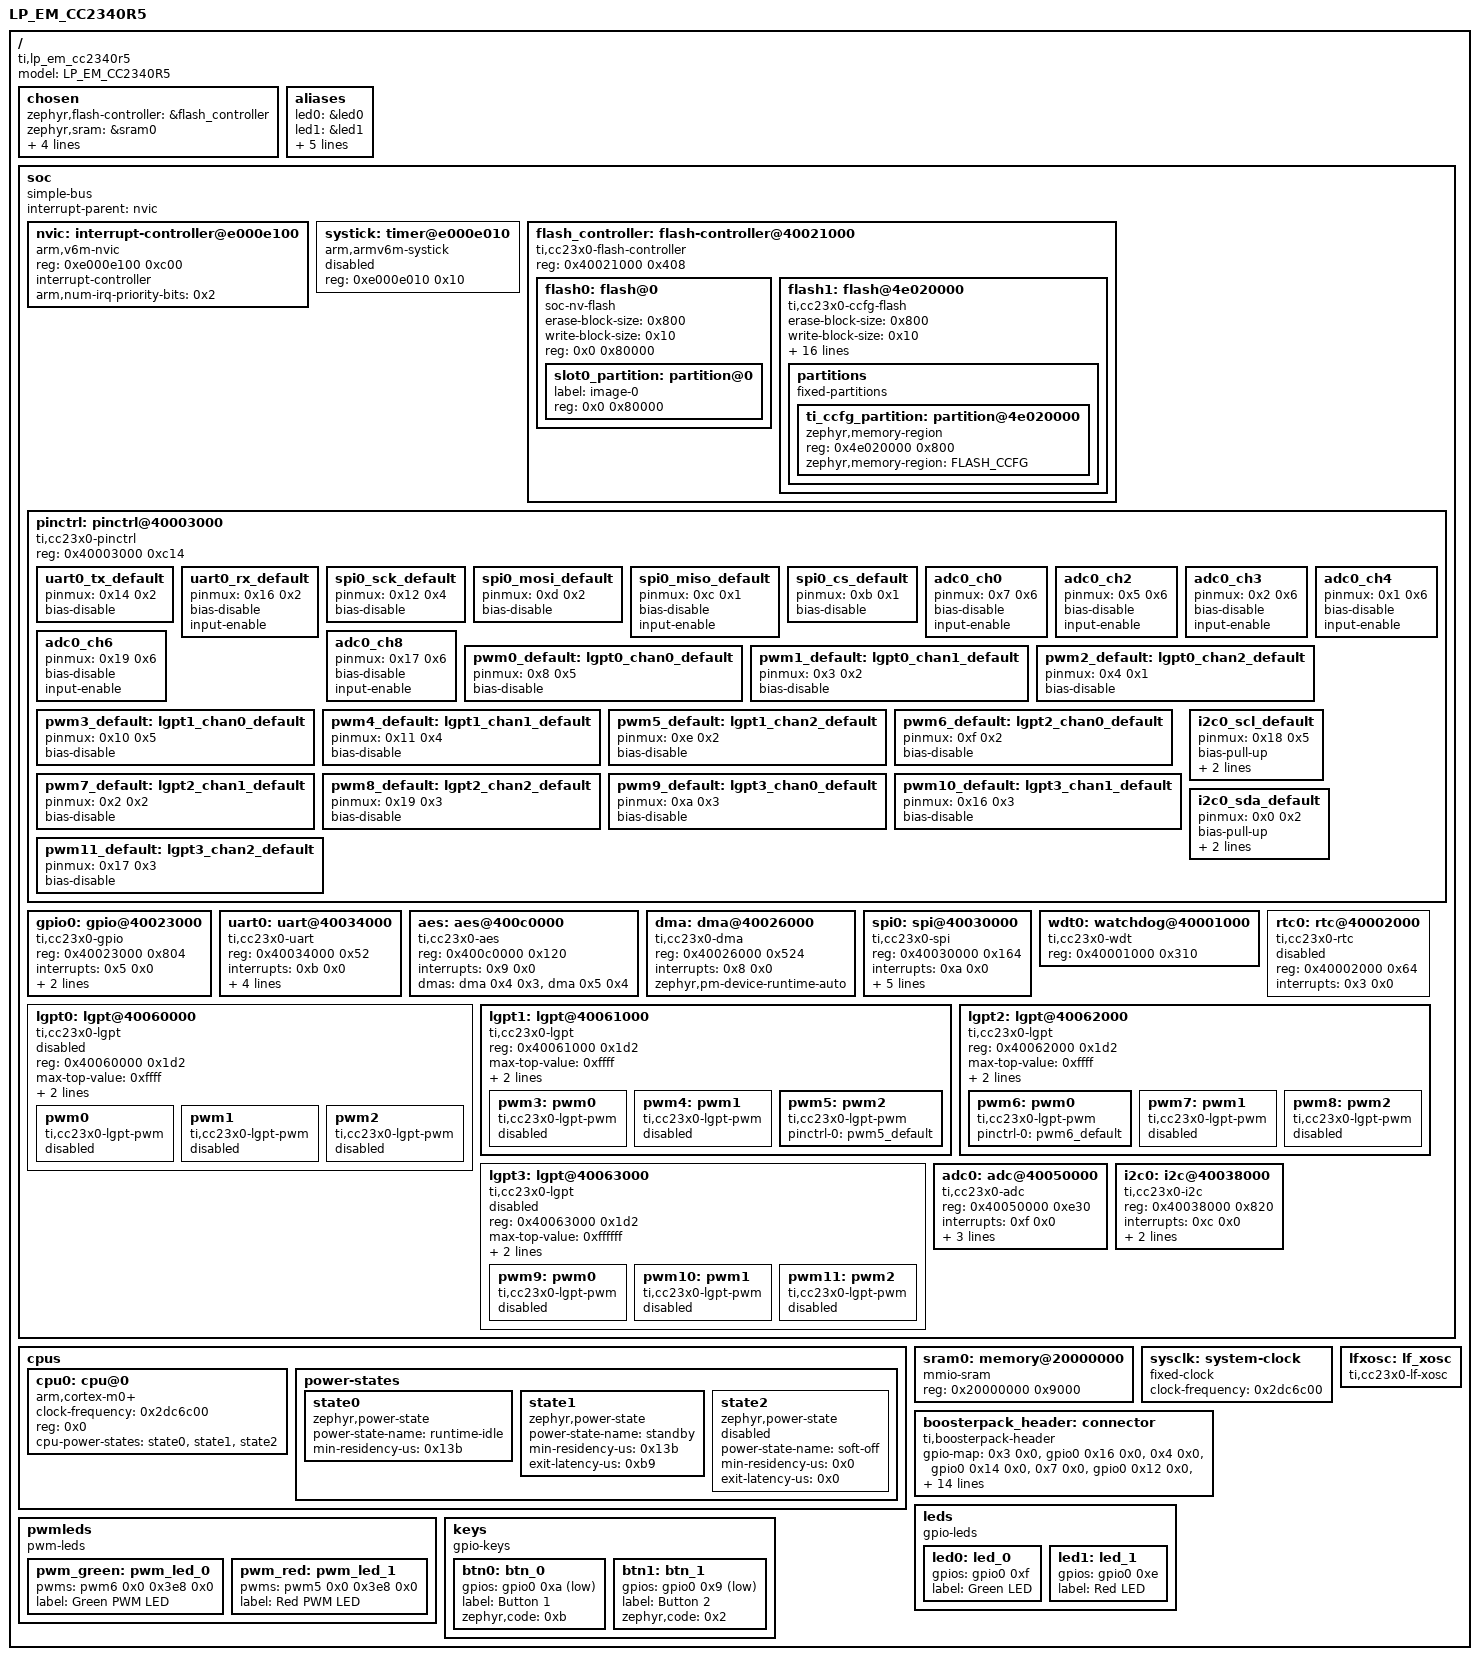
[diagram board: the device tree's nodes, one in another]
/dts-v1/;

/* node '/' defined in zephyr/dts/common/skeleton.dtsi:9 */
/ {
	#address-cells = < 0x1 >;         /* in zephyr/dts/common/skeleton.dtsi:10 */
	#size-cells = < 0x1 >;            /* in zephyr/dts/common/skeleton.dtsi:11 */
	model = "LP_EM_CC2340R5";         /* in zephyr/boards/ti/lp_em_cc2340r5/lp_em_cc2340r5.dts:18 */
	compatible = "ti,lp_em_cc2340r5"; /* in zephyr/boards/ti/lp_em_cc2340r5/lp_em_cc2340r5.dts:19 */

	/* node '/chosen' defined in zephyr/dts/common/skeleton.dtsi:13 */
	chosen {
		zephyr,flash-controller = &flash_controller; /* in zephyr/dts/arm/ti/cc23x0.dtsi:13 */
		zephyr,sram = &sram0;                        /* in zephyr/boards/ti/lp_em_cc2340r5/lp_em_cc2340r5.dts:22 */
		zephyr,flash = &flash0;                      /* in zephyr/boards/ti/lp_em_cc2340r5/lp_em_cc2340r5.dts:23 */
		zephyr,code-partition = &slot0_partition;    /* in zephyr/boards/ti/lp_em_cc2340r5/lp_em_cc2340r5.dts:24 */
		zephyr,console = &uart0;                     /* in zephyr/boards/ti/lp_em_cc2340r5/lp_em_cc2340r5.dts:25 */
		zephyr,shell-uart = &uart0;                  /* in zephyr/boards/ti/lp_em_cc2340r5/lp_em_cc2340r5.dts:26 */
	};

	/* node '/aliases' defined in zephyr/dts/common/skeleton.dtsi:15 */
	aliases {
		led0 = &led0;          /* in zephyr/boards/ti/lp_em_cc2340r5/lp_em_cc2340r5.dts:30 */
		led1 = &led1;          /* in zephyr/boards/ti/lp_em_cc2340r5/lp_em_cc2340r5.dts:31 */
		sw0 = &btn0;           /* in zephyr/boards/ti/lp_em_cc2340r5/lp_em_cc2340r5.dts:32 */
		sw1 = &btn1;           /* in zephyr/boards/ti/lp_em_cc2340r5/lp_em_cc2340r5.dts:33 */
		watchdog0 = &wdt0;     /* in zephyr/boards/ti/lp_em_cc2340r5/lp_em_cc2340r5.dts:34 */
		pwm-led0 = &pwm_green; /* in zephyr/boards/ti/lp_em_cc2340r5/lp_em_cc2340r5.dts:35 */
		pwm-led1 = &pwm_red;   /* in zephyr/boards/ti/lp_em_cc2340r5/lp_em_cc2340r5.dts:36 */
	};

	/* node '/soc' defined in zephyr/dts/arm/armv6-m.dtsi:6 */
	soc {
		#address-cells = < 0x1 >;     /* in zephyr/dts/arm/armv6-m.dtsi:7 */
		#size-cells = < 0x1 >;        /* in zephyr/dts/arm/armv6-m.dtsi:8 */
		compatible = "simple-bus";    /* in zephyr/dts/arm/armv6-m.dtsi:9 */
		interrupt-parent = < &nvic >; /* in zephyr/dts/arm/armv6-m.dtsi:10 */
		ranges;                       /* in zephyr/dts/arm/armv6-m.dtsi:11 */

		/* node '/soc/interrupt-controller@e000e100' defined in zephyr/dts/arm/armv6-m.dtsi:13 */
		nvic: interrupt-controller@e000e100 {
			#address-cells = < 0x1 >;            /* in zephyr/dts/arm/armv6-m.dtsi:14 */
			compatible = "arm,v6m-nvic";         /* in zephyr/dts/arm/armv6-m.dtsi:15 */
			reg = < 0xe000e100 0xc00 >;          /* in zephyr/dts/arm/armv6-m.dtsi:16 */
			interrupt-controller;                /* in zephyr/dts/arm/armv6-m.dtsi:17 */
			#interrupt-cells = < 0x2 >;          /* in zephyr/dts/arm/armv6-m.dtsi:18 */
			arm,num-irq-priority-bits = < 0x2 >; /* in zephyr/dts/arm/ti/cc23x0.dtsi:283 */
			phandle = < 0x1 >;                   /* in zephyr/dts/arm/armv6-m.dtsi:10 */
		};

		/* node '/soc/timer@e000e010' defined in zephyr/dts/arm/armv6-m.dtsi:21 */
		systick: timer@e000e010 {
			compatible = "arm,armv6m-systick"; /* in zephyr/dts/arm/armv6-m.dtsi:22 */
			reg = < 0xe000e010 0x10 >;         /* in zephyr/dts/arm/armv6-m.dtsi:23 */
			status = "disabled";               /* in zephyr/dts/arm/ti/cc23x0.dtsi:287 */
		};

		/* node '/soc/flash-controller@40021000' defined in zephyr/dts/arm/ti/cc23x0.dtsi:64 */
		flash_controller: flash-controller@40021000 {
			compatible = "ti,cc23x0-flash-controller"; /* in zephyr/dts/arm/ti/cc23x0.dtsi:65 */
			reg = < 0x40021000 0x408 >;                /* in zephyr/dts/arm/ti/cc23x0.dtsi:66 */
			#address-cells = < 0x1 >;                  /* in zephyr/dts/arm/ti/cc23x0.dtsi:67 */
			#size-cells = < 0x1 >;                     /* in zephyr/dts/arm/ti/cc23x0.dtsi:68 */

			/* node '/soc/flash-controller@40021000/flash@0' defined in zephyr/dts/arm/ti/cc23x0.dtsi:71 */
			flash0: flash@0 {
				compatible = "soc-nv-flash";  /* in zephyr/dts/arm/ti/cc23x0.dtsi:72 */
				erase-block-size = < 0x800 >; /* in zephyr/dts/arm/ti/cc23x0.dtsi:73 */
				write-block-size = < 0x10 >;  /* in zephyr/dts/arm/ti/cc23x0.dtsi:74 */
				reg = < 0x0 0x80000 >;        /* in zephyr/dts/arm/ti/cc2340r5.dtsi:19 */
				#address-cells = < 0x1 >;     /* in zephyr/dts/arm/ti/cc2340r5.dtsi:20 */
				#size-cells = < 0x1 >;        /* in zephyr/dts/arm/ti/cc2340r5.dtsi:21 */

				/* node '/soc/flash-controller@40021000/flash@0/partition@0' defined in zephyr/dts/arm/ti/cc2340r5.dtsi:23 */
				slot0_partition: partition@0 {
					label = "image-0";     /* in zephyr/dts/arm/ti/cc2340r5.dtsi:24 */
					reg = < 0x0 0x80000 >; /* in zephyr/dts/arm/ti/cc2340r5.dtsi:25 */
				};
			};

			/* node '/soc/flash-controller@40021000/flash@4e020000' defined in zephyr/dts/arm/ti/cc23x0.dtsi:78 */
			flash1: flash@4e020000 {
				compatible = "ti,cc23x0-ccfg-flash",
				             "soc-nv-flash";               /* in zephyr/dts/arm/ti/cc23x0.dtsi:79 */
				erase-block-size = < 0x800 >;              /* in zephyr/dts/arm/ti/cc23x0.dtsi:80 */
				write-block-size = < 0x10 >;               /* in zephyr/dts/arm/ti/cc23x0.dtsi:81 */
				reg = < 0x4e020000 0x800 >;                /* in zephyr/dts/arm/ti/cc2340r5.dtsi:31 */
				ti,bldr-vtor-flash = < 0x0 >;              /* in zephyr/dts/arm/ti/cc2340r5.dtsi:32 */
				ti,serial-io-cfg-index = < 0x0 >;          /* in zephyr/dts/arm/ti/cc2340r5.dtsi:33 */
				ti,debug-port;                             /* in zephyr/dts/arm/ti/cc2340r5.dtsi:34 */
				ti,energy-trace;                           /* in zephyr/dts/arm/ti/cc2340r5.dtsi:35 */
				ti,flash-verify;                           /* in zephyr/dts/arm/ti/cc2340r5.dtsi:36 */
				ti,flash-program;                          /* in zephyr/dts/arm/ti/cc2340r5.dtsi:37 */
				ti,chip-erase;                             /* in zephyr/dts/arm/ti/cc2340r5.dtsi:38 */
				ti,ret-to-factory;                         /* in zephyr/dts/arm/ti/cc2340r5.dtsi:39 */
				ti,wr-er-prot-sect0-31 = < 0xffffffff >;   /* in zephyr/dts/arm/ti/cc2340r5.dtsi:40 */
				ti,wr-er-prot-sect32-255 = < 0xffffffff >; /* in zephyr/dts/arm/ti/cc2340r5.dtsi:41 */
				ti,wr-er-prot-ccfg-sect = < 0x0 >;         /* in zephyr/dts/arm/ti/cc2340r5.dtsi:42 */
				ti,wr-er-prot-fcfg-sect = < 0x0 >;         /* in zephyr/dts/arm/ti/cc2340r5.dtsi:43 */
				ti,wr-er-prot-engr-sect = < 0x0 >;         /* in zephyr/dts/arm/ti/cc2340r5.dtsi:44 */
				ti,chip-er-retain-sect0-31 = < 0x0 >;      /* in zephyr/dts/arm/ti/cc2340r5.dtsi:45 */
				ti,chip-er-retain-sect32-255 = < 0x0 >;    /* in zephyr/dts/arm/ti/cc2340r5.dtsi:46 */

				/* node '/soc/flash-controller@40021000/flash@4e020000/partitions' defined in zephyr/dts/arm/ti/cc2340r5.dtsi:48 */
				partitions {
					compatible = "fixed-partitions"; /* in zephyr/dts/arm/ti/cc2340r5.dtsi:49 */
					#address-cells = < 0x1 >;        /* in zephyr/dts/arm/ti/cc2340r5.dtsi:50 */
					#size-cells = < 0x1 >;           /* in zephyr/dts/arm/ti/cc2340r5.dtsi:51 */

					/* node '/soc/flash-controller@40021000/flash@4e020000/partitions/partition@4e020000' defined in zephyr/dts/arm/ti/cc2340r5.dtsi:53 */
					ti_ccfg_partition: partition@4e020000 {
						compatible = "zephyr,memory-region"; /* in zephyr/dts/arm/ti/cc2340r5.dtsi:54 */
						reg = < 0x4e020000 0x800 >;          /* in zephyr/dts/arm/ti/cc2340r5.dtsi:55 */
						zephyr,memory-region = "FLASH_CCFG"; /* in zephyr/dts/arm/ti/cc2340r5.dtsi:56 */
					};
				};
			};
		};

		/* node '/soc/pinctrl@40003000' defined in zephyr/dts/arm/ti/cc23x0.dtsi:85 */
		pinctrl: pinctrl@40003000 {
			compatible = "ti,cc23x0-pinctrl"; /* in zephyr/dts/arm/ti/cc23x0.dtsi:86 */
			reg = < 0x40003000 0xc14 >;       /* in zephyr/dts/arm/ti/cc23x0.dtsi:87 */

			/* node '/soc/pinctrl@40003000/uart0_tx_default' defined in zephyr/boards/ti/lp_em_cc2340r5/lp_em_cc2340r5-pinctrl.dtsi:12 */
			uart0_tx_default: uart0_tx_default {
				pinmux = < 0x14 0x2 >; /* in zephyr/boards/ti/lp_em_cc2340r5/lp_em_cc2340r5-pinctrl.dtsi:13 */
				bias-disable;          /* in zephyr/boards/ti/lp_em_cc2340r5/lp_em_cc2340r5-pinctrl.dtsi:14 */
				phandle = < 0x5 >;     /* in zephyr/boards/ti/lp_em_cc2340r5/lp_em_cc2340r5.dts:95 */
			};

			/* node '/soc/pinctrl@40003000/uart0_rx_default' defined in zephyr/boards/ti/lp_em_cc2340r5/lp_em_cc2340r5-pinctrl.dtsi:17 */
			uart0_rx_default: uart0_rx_default {
				pinmux = < 0x16 0x2 >; /* in zephyr/boards/ti/lp_em_cc2340r5/lp_em_cc2340r5-pinctrl.dtsi:18 */
				bias-disable;          /* in zephyr/boards/ti/lp_em_cc2340r5/lp_em_cc2340r5-pinctrl.dtsi:19 */
				input-enable;          /* in zephyr/boards/ti/lp_em_cc2340r5/lp_em_cc2340r5-pinctrl.dtsi:20 */
				phandle = < 0x4 >;     /* in zephyr/boards/ti/lp_em_cc2340r5/lp_em_cc2340r5.dts:95 */
			};

			/* node '/soc/pinctrl@40003000/spi0_sck_default' defined in zephyr/boards/ti/lp_em_cc2340r5/lp_em_cc2340r5-pinctrl.dtsi:24 */
			spi0_sck_default: spi0_sck_default {
				pinmux = < 0x12 0x4 >; /* in zephyr/boards/ti/lp_em_cc2340r5/lp_em_cc2340r5-pinctrl.dtsi:25 */
				bias-disable;          /* in zephyr/boards/ti/lp_em_cc2340r5/lp_em_cc2340r5-pinctrl.dtsi:26 */
				phandle = < 0x8 >;     /* in zephyr/boards/ti/lp_em_cc2340r5/lp_em_cc2340r5.dts:109 */
			};

			/* node '/soc/pinctrl@40003000/spi0_mosi_default' defined in zephyr/boards/ti/lp_em_cc2340r5/lp_em_cc2340r5-pinctrl.dtsi:29 */
			spi0_mosi_default: spi0_mosi_default {
				pinmux = < 0xd 0x2 >; /* in zephyr/boards/ti/lp_em_cc2340r5/lp_em_cc2340r5-pinctrl.dtsi:30 */
				bias-disable;         /* in zephyr/boards/ti/lp_em_cc2340r5/lp_em_cc2340r5-pinctrl.dtsi:31 */
				phandle = < 0x9 >;    /* in zephyr/boards/ti/lp_em_cc2340r5/lp_em_cc2340r5.dts:109 */
			};

			/* node '/soc/pinctrl@40003000/spi0_miso_default' defined in zephyr/boards/ti/lp_em_cc2340r5/lp_em_cc2340r5-pinctrl.dtsi:34 */
			spi0_miso_default: spi0_miso_default {
				pinmux = < 0xc 0x1 >; /* in zephyr/boards/ti/lp_em_cc2340r5/lp_em_cc2340r5-pinctrl.dtsi:35 */
				bias-disable;         /* in zephyr/boards/ti/lp_em_cc2340r5/lp_em_cc2340r5-pinctrl.dtsi:36 */
				input-enable;         /* in zephyr/boards/ti/lp_em_cc2340r5/lp_em_cc2340r5-pinctrl.dtsi:37 */
				phandle = < 0xa >;    /* in zephyr/boards/ti/lp_em_cc2340r5/lp_em_cc2340r5.dts:109 */
			};

			/* node '/soc/pinctrl@40003000/spi0_cs_default' defined in zephyr/boards/ti/lp_em_cc2340r5/lp_em_cc2340r5-pinctrl.dtsi:40 */
			spi0_cs_default: spi0_cs_default {
				pinmux = < 0xb 0x1 >; /* in zephyr/boards/ti/lp_em_cc2340r5/lp_em_cc2340r5-pinctrl.dtsi:41 */
				bias-disable;         /* in zephyr/boards/ti/lp_em_cc2340r5/lp_em_cc2340r5-pinctrl.dtsi:42 */
				phandle = < 0xb >;    /* in zephyr/boards/ti/lp_em_cc2340r5/lp_em_cc2340r5.dts:109 */
			};

			/* node '/soc/pinctrl@40003000/adc0_ch0' defined in zephyr/boards/ti/lp_em_cc2340r5/lp_em_cc2340r5-pinctrl.dtsi:46 */
			adc0_ch0: adc0_ch0 {
				pinmux = < 0x7 0x6 >; /* in zephyr/boards/ti/lp_em_cc2340r5/lp_em_cc2340r5-pinctrl.dtsi:47 */
				bias-disable;         /* in zephyr/boards/ti/lp_em_cc2340r5/lp_em_cc2340r5-pinctrl.dtsi:48 */
				input-enable;         /* in zephyr/boards/ti/lp_em_cc2340r5/lp_em_cc2340r5-pinctrl.dtsi:49 */
				phandle = < 0xe >;    /* in zephyr/boards/ti/lp_em_cc2340r5/lp_em_cc2340r5.dts:122 */
			};

			/* node '/soc/pinctrl@40003000/adc0_ch2' defined in zephyr/boards/ti/lp_em_cc2340r5/lp_em_cc2340r5-pinctrl.dtsi:52 */
			adc0_ch2: adc0_ch2 {
				pinmux = < 0x5 0x6 >; /* in zephyr/boards/ti/lp_em_cc2340r5/lp_em_cc2340r5-pinctrl.dtsi:53 */
				bias-disable;         /* in zephyr/boards/ti/lp_em_cc2340r5/lp_em_cc2340r5-pinctrl.dtsi:54 */
				input-enable;         /* in zephyr/boards/ti/lp_em_cc2340r5/lp_em_cc2340r5-pinctrl.dtsi:55 */
				phandle = < 0xf >;    /* in zephyr/boards/ti/lp_em_cc2340r5/lp_em_cc2340r5.dts:122 */
			};

			/* node '/soc/pinctrl@40003000/adc0_ch3' defined in zephyr/boards/ti/lp_em_cc2340r5/lp_em_cc2340r5-pinctrl.dtsi:58 */
			adc0_ch3: adc0_ch3 {
				pinmux = < 0x2 0x6 >; /* in zephyr/boards/ti/lp_em_cc2340r5/lp_em_cc2340r5-pinctrl.dtsi:59 */
				bias-disable;         /* in zephyr/boards/ti/lp_em_cc2340r5/lp_em_cc2340r5-pinctrl.dtsi:60 */
				input-enable;         /* in zephyr/boards/ti/lp_em_cc2340r5/lp_em_cc2340r5-pinctrl.dtsi:61 */
				phandle = < 0x10 >;   /* in zephyr/boards/ti/lp_em_cc2340r5/lp_em_cc2340r5.dts:122 */
			};

			/* node '/soc/pinctrl@40003000/adc0_ch4' defined in zephyr/boards/ti/lp_em_cc2340r5/lp_em_cc2340r5-pinctrl.dtsi:64 */
			adc0_ch4: adc0_ch4 {
				pinmux = < 0x1 0x6 >; /* in zephyr/boards/ti/lp_em_cc2340r5/lp_em_cc2340r5-pinctrl.dtsi:65 */
				bias-disable;         /* in zephyr/boards/ti/lp_em_cc2340r5/lp_em_cc2340r5-pinctrl.dtsi:66 */
				input-enable;         /* in zephyr/boards/ti/lp_em_cc2340r5/lp_em_cc2340r5-pinctrl.dtsi:67 */
				phandle = < 0x11 >;   /* in zephyr/boards/ti/lp_em_cc2340r5/lp_em_cc2340r5.dts:122 */
			};

			/* node '/soc/pinctrl@40003000/adc0_ch6' defined in zephyr/boards/ti/lp_em_cc2340r5/lp_em_cc2340r5-pinctrl.dtsi:70 */
			adc0_ch6: adc0_ch6 {
				pinmux = < 0x19 0x6 >; /* in zephyr/boards/ti/lp_em_cc2340r5/lp_em_cc2340r5-pinctrl.dtsi:71 */
				bias-disable;          /* in zephyr/boards/ti/lp_em_cc2340r5/lp_em_cc2340r5-pinctrl.dtsi:72 */
				input-enable;          /* in zephyr/boards/ti/lp_em_cc2340r5/lp_em_cc2340r5-pinctrl.dtsi:73 */
				phandle = < 0x12 >;    /* in zephyr/boards/ti/lp_em_cc2340r5/lp_em_cc2340r5.dts:122 */
			};

			/* node '/soc/pinctrl@40003000/adc0_ch8' defined in zephyr/boards/ti/lp_em_cc2340r5/lp_em_cc2340r5-pinctrl.dtsi:76 */
			adc0_ch8: adc0_ch8 {
				pinmux = < 0x17 0x6 >; /* in zephyr/boards/ti/lp_em_cc2340r5/lp_em_cc2340r5-pinctrl.dtsi:77 */
				bias-disable;          /* in zephyr/boards/ti/lp_em_cc2340r5/lp_em_cc2340r5-pinctrl.dtsi:78 */
				input-enable;          /* in zephyr/boards/ti/lp_em_cc2340r5/lp_em_cc2340r5-pinctrl.dtsi:79 */
				phandle = < 0x13 >;    /* in zephyr/boards/ti/lp_em_cc2340r5/lp_em_cc2340r5.dts:122 */
			};

			/* node '/soc/pinctrl@40003000/lgpt0_chan0_default' defined in zephyr/boards/ti/lp_em_cc2340r5/lp_em_cc2340r5-pinctrl.dtsi:83 */
			pwm0_default: lgpt0_chan0_default {
				pinmux = < 0x8 0x5 >; /* in zephyr/boards/ti/lp_em_cc2340r5/lp_em_cc2340r5-pinctrl.dtsi:84 */
				bias-disable;         /* in zephyr/boards/ti/lp_em_cc2340r5/lp_em_cc2340r5-pinctrl.dtsi:85 */
			};

			/* node '/soc/pinctrl@40003000/lgpt0_chan1_default' defined in zephyr/boards/ti/lp_em_cc2340r5/lp_em_cc2340r5-pinctrl.dtsi:88 */
			pwm1_default: lgpt0_chan1_default {
				pinmux = < 0x3 0x2 >; /* in zephyr/boards/ti/lp_em_cc2340r5/lp_em_cc2340r5-pinctrl.dtsi:89 */
				bias-disable;         /* in zephyr/boards/ti/lp_em_cc2340r5/lp_em_cc2340r5-pinctrl.dtsi:90 */
			};

			/* node '/soc/pinctrl@40003000/lgpt0_chan2_default' defined in zephyr/boards/ti/lp_em_cc2340r5/lp_em_cc2340r5-pinctrl.dtsi:93 */
			pwm2_default: lgpt0_chan2_default {
				pinmux = < 0x4 0x1 >; /* in zephyr/boards/ti/lp_em_cc2340r5/lp_em_cc2340r5-pinctrl.dtsi:94 */
				bias-disable;         /* in zephyr/boards/ti/lp_em_cc2340r5/lp_em_cc2340r5-pinctrl.dtsi:95 */
			};

			/* node '/soc/pinctrl@40003000/lgpt1_chan0_default' defined in zephyr/boards/ti/lp_em_cc2340r5/lp_em_cc2340r5-pinctrl.dtsi:99 */
			pwm3_default: lgpt1_chan0_default {
				pinmux = < 0x10 0x5 >; /* in zephyr/boards/ti/lp_em_cc2340r5/lp_em_cc2340r5-pinctrl.dtsi:100 */
				bias-disable;          /* in zephyr/boards/ti/lp_em_cc2340r5/lp_em_cc2340r5-pinctrl.dtsi:101 */
			};

			/* node '/soc/pinctrl@40003000/lgpt1_chan1_default' defined in zephyr/boards/ti/lp_em_cc2340r5/lp_em_cc2340r5-pinctrl.dtsi:104 */
			pwm4_default: lgpt1_chan1_default {
				pinmux = < 0x11 0x4 >; /* in zephyr/boards/ti/lp_em_cc2340r5/lp_em_cc2340r5-pinctrl.dtsi:105 */
				bias-disable;          /* in zephyr/boards/ti/lp_em_cc2340r5/lp_em_cc2340r5-pinctrl.dtsi:106 */
			};

			/* node '/soc/pinctrl@40003000/lgpt1_chan2_default' defined in zephyr/boards/ti/lp_em_cc2340r5/lp_em_cc2340r5-pinctrl.dtsi:109 */
			pwm5_default: lgpt1_chan2_default {
				pinmux = < 0xe 0x2 >; /* in zephyr/boards/ti/lp_em_cc2340r5/lp_em_cc2340r5-pinctrl.dtsi:110 */
				bias-disable;         /* in zephyr/boards/ti/lp_em_cc2340r5/lp_em_cc2340r5-pinctrl.dtsi:111 */
				phandle = < 0xc >;    /* in zephyr/boards/ti/lp_em_cc2340r5/lp_em_cc2340r5.dts:142 */
			};

			/* node '/soc/pinctrl@40003000/lgpt2_chan0_default' defined in zephyr/boards/ti/lp_em_cc2340r5/lp_em_cc2340r5-pinctrl.dtsi:115 */
			pwm6_default: lgpt2_chan0_default {
				pinmux = < 0xf 0x2 >; /* in zephyr/boards/ti/lp_em_cc2340r5/lp_em_cc2340r5-pinctrl.dtsi:116 */
				bias-disable;         /* in zephyr/boards/ti/lp_em_cc2340r5/lp_em_cc2340r5-pinctrl.dtsi:117 */
				phandle = < 0xd >;    /* in zephyr/boards/ti/lp_em_cc2340r5/lp_em_cc2340r5.dts:148 */
			};

			/* node '/soc/pinctrl@40003000/lgpt2_chan1_default' defined in zephyr/boards/ti/lp_em_cc2340r5/lp_em_cc2340r5-pinctrl.dtsi:120 */
			pwm7_default: lgpt2_chan1_default {
				pinmux = < 0x2 0x2 >; /* in zephyr/boards/ti/lp_em_cc2340r5/lp_em_cc2340r5-pinctrl.dtsi:121 */
				bias-disable;         /* in zephyr/boards/ti/lp_em_cc2340r5/lp_em_cc2340r5-pinctrl.dtsi:122 */
			};

			/* node '/soc/pinctrl@40003000/lgpt2_chan2_default' defined in zephyr/boards/ti/lp_em_cc2340r5/lp_em_cc2340r5-pinctrl.dtsi:125 */
			pwm8_default: lgpt2_chan2_default {
				pinmux = < 0x19 0x3 >; /* in zephyr/boards/ti/lp_em_cc2340r5/lp_em_cc2340r5-pinctrl.dtsi:126 */
				bias-disable;          /* in zephyr/boards/ti/lp_em_cc2340r5/lp_em_cc2340r5-pinctrl.dtsi:127 */
			};

			/* node '/soc/pinctrl@40003000/lgpt3_chan0_default' defined in zephyr/boards/ti/lp_em_cc2340r5/lp_em_cc2340r5-pinctrl.dtsi:131 */
			pwm9_default: lgpt3_chan0_default {
				pinmux = < 0xa 0x3 >; /* in zephyr/boards/ti/lp_em_cc2340r5/lp_em_cc2340r5-pinctrl.dtsi:132 */
				bias-disable;         /* in zephyr/boards/ti/lp_em_cc2340r5/lp_em_cc2340r5-pinctrl.dtsi:133 */
			};

			/* node '/soc/pinctrl@40003000/lgpt3_chan1_default' defined in zephyr/boards/ti/lp_em_cc2340r5/lp_em_cc2340r5-pinctrl.dtsi:136 */
			pwm10_default: lgpt3_chan1_default {
				pinmux = < 0x16 0x3 >; /* in zephyr/boards/ti/lp_em_cc2340r5/lp_em_cc2340r5-pinctrl.dtsi:137 */
				bias-disable;          /* in zephyr/boards/ti/lp_em_cc2340r5/lp_em_cc2340r5-pinctrl.dtsi:138 */
			};

			/* node '/soc/pinctrl@40003000/lgpt3_chan2_default' defined in zephyr/boards/ti/lp_em_cc2340r5/lp_em_cc2340r5-pinctrl.dtsi:141 */
			pwm11_default: lgpt3_chan2_default {
				pinmux = < 0x17 0x3 >; /* in zephyr/boards/ti/lp_em_cc2340r5/lp_em_cc2340r5-pinctrl.dtsi:142 */
				bias-disable;          /* in zephyr/boards/ti/lp_em_cc2340r5/lp_em_cc2340r5-pinctrl.dtsi:143 */
			};

			/* node '/soc/pinctrl@40003000/i2c0_scl_default' defined in zephyr/boards/ti/lp_em_cc2340r5/lp_em_cc2340r5-pinctrl.dtsi:147 */
			i2c0_scl_default: i2c0_scl_default {
				pinmux = < 0x18 0x5 >; /* in zephyr/boards/ti/lp_em_cc2340r5/lp_em_cc2340r5-pinctrl.dtsi:148 */
				bias-pull-up;          /* in zephyr/boards/ti/lp_em_cc2340r5/lp_em_cc2340r5-pinctrl.dtsi:149 */
				drive-open-drain;      /* in zephyr/boards/ti/lp_em_cc2340r5/lp_em_cc2340r5-pinctrl.dtsi:150 */
				input-enable;          /* in zephyr/boards/ti/lp_em_cc2340r5/lp_em_cc2340r5-pinctrl.dtsi:151 */
				phandle = < 0x14 >;    /* in zephyr/boards/ti/lp_em_cc2340r5/lp_em_cc2340r5.dts:155 */
			};

			/* node '/soc/pinctrl@40003000/i2c0_sda_default' defined in zephyr/boards/ti/lp_em_cc2340r5/lp_em_cc2340r5-pinctrl.dtsi:153 */
			i2c0_sda_default: i2c0_sda_default {
				pinmux = < 0x0 0x2 >; /* in zephyr/boards/ti/lp_em_cc2340r5/lp_em_cc2340r5-pinctrl.dtsi:154 */
				bias-pull-up;         /* in zephyr/boards/ti/lp_em_cc2340r5/lp_em_cc2340r5-pinctrl.dtsi:155 */
				drive-open-drain;     /* in zephyr/boards/ti/lp_em_cc2340r5/lp_em_cc2340r5-pinctrl.dtsi:156 */
				input-enable;         /* in zephyr/boards/ti/lp_em_cc2340r5/lp_em_cc2340r5-pinctrl.dtsi:157 */
				phandle = < 0x15 >;   /* in zephyr/boards/ti/lp_em_cc2340r5/lp_em_cc2340r5.dts:155 */
			};
		};

		/* node '/soc/gpio@40023000' defined in zephyr/dts/arm/ti/cc23x0.dtsi:90 */
		gpio0: gpio@40023000 {
			compatible = "ti,cc23x0-gpio"; /* in zephyr/dts/arm/ti/cc23x0.dtsi:91 */
			reg = < 0x40023000 0x804 >;    /* in zephyr/dts/arm/ti/cc23x0.dtsi:92 */
			interrupts = < 0x5 0x0 >;      /* in zephyr/dts/arm/ti/cc23x0.dtsi:93 */
			gpio-controller;               /* in zephyr/dts/arm/ti/cc23x0.dtsi:95 */
			#gpio-cells = < 0x2 >;         /* in zephyr/dts/arm/ti/cc23x0.dtsi:96 */
			ngpios = < 0x1a >;             /* in zephyr/dts/arm/ti/cc23x0.dtsi:97 */
			status = "okay";               /* in zephyr/boards/ti/lp_em_cc2340r5/lp_em_cc2340r5.dts:89 */
			phandle = < 0x17 >;            /* in zephyr/boards/ti/lp_em_cc2340r5/boosterpack_connector.dtsi:12 */
		};

		/* node '/soc/uart@40034000' defined in zephyr/dts/arm/ti/cc23x0.dtsi:100 */
		uart0: uart@40034000 {
			compatible = "ti,cc23x0-uart";                       /* in zephyr/dts/arm/ti/cc23x0.dtsi:101 */
			reg = < 0x40034000 0x52 >;                           /* in zephyr/dts/arm/ti/cc23x0.dtsi:102 */
			interrupts = < 0xb 0x0 >;                            /* in zephyr/dts/arm/ti/cc23x0.dtsi:103 */
			clocks = < &sysclk >;                                /* in zephyr/dts/arm/ti/cc23x0.dtsi:104 */
			dmas = < &dma 0x2 0x6 >,
			       < &dma 0x3 0x7 >;                             /* in zephyr/dts/arm/ti/cc23x0.dtsi:105 */
			dma-names = "tx",
			            "rx";                                    /* in zephyr/dts/arm/ti/cc23x0.dtsi:106 */
			status = "okay";                                     /* in zephyr/boards/ti/lp_em_cc2340r5/lp_em_cc2340r5.dts:93 */
			current-speed = < 0x1c200 >;                         /* in zephyr/boards/ti/lp_em_cc2340r5/lp_em_cc2340r5.dts:94 */
			pinctrl-0 = < &uart0_rx_default &uart0_tx_default >; /* in zephyr/boards/ti/lp_em_cc2340r5/lp_em_cc2340r5.dts:95 */
			pinctrl-names = "default";                           /* in zephyr/boards/ti/lp_em_cc2340r5/lp_em_cc2340r5.dts:96 */
		};

		/* node '/soc/aes@400c0000' defined in zephyr/dts/arm/ti/cc23x0.dtsi:110 */
		aes: aes@400c0000 {
			compatible = "ti,cc23x0-aes"; /* in zephyr/dts/arm/ti/cc23x0.dtsi:111 */
			reg = < 0x400c0000 0x120 >;   /* in zephyr/dts/arm/ti/cc23x0.dtsi:112 */
			interrupts = < 0x9 0x0 >;     /* in zephyr/dts/arm/ti/cc23x0.dtsi:113 */
			dmas = < &dma 0x4 0x3 >,
			       < &dma 0x5 0x4 >;      /* in zephyr/dts/arm/ti/cc23x0.dtsi:114 */
			dma-names = "cha",
			            "chb";            /* in zephyr/dts/arm/ti/cc23x0.dtsi:115 */
			status = "okay";              /* in zephyr/boards/ti/lp_em_cc2340r5/lp_em_cc2340r5.dts:100 */
		};

		/* node '/soc/dma@40026000' defined in zephyr/dts/arm/ti/cc23x0.dtsi:119 */
		dma: dma@40026000 {
			compatible = "ti,cc23x0-dma";  /* in zephyr/dts/arm/ti/cc23x0.dtsi:120 */
			reg = < 0x40026000 0x524 >;    /* in zephyr/dts/arm/ti/cc23x0.dtsi:121 */
			interrupts = < 0x8 0x0 >;      /* in zephyr/dts/arm/ti/cc23x0.dtsi:122 */
			#dma-cells = < 0x2 >;          /* in zephyr/dts/arm/ti/cc23x0.dtsi:123 */
			zephyr,pm-device-runtime-auto; /* in zephyr/dts/arm/ti/cc23x0.dtsi:124 */
			status = "okay";               /* in zephyr/boards/ti/lp_em_cc2340r5/lp_em_cc2340r5.dts:104 */
			phandle = < 0x3 >;             /* in zephyr/dts/arm/ti/cc23x0.dtsi:105 */
		};

		/* node '/soc/spi@40030000' defined in zephyr/dts/arm/ti/cc23x0.dtsi:128 */
		spi0: spi@40030000 {
			compatible = "ti,cc23x0-spi";                                                             /* in zephyr/dts/arm/ti/cc23x0.dtsi:129 */
			#address-cells = < 0x1 >;                                                                 /* in zephyr/dts/arm/ti/cc23x0.dtsi:130 */
			#size-cells = < 0x0 >;                                                                    /* in zephyr/dts/arm/ti/cc23x0.dtsi:131 */
			reg = < 0x40030000 0x164 >;                                                               /* in zephyr/dts/arm/ti/cc23x0.dtsi:132 */
			interrupts = < 0xa 0x0 >;                                                                 /* in zephyr/dts/arm/ti/cc23x0.dtsi:133 */
			dmas = < &dma 0x0 0x0 >,
			       < &dma 0x1 0x1 >;                                                                  /* in zephyr/dts/arm/ti/cc23x0.dtsi:134 */
			dma-names = "tx",
			            "rx";                                                                         /* in zephyr/dts/arm/ti/cc23x0.dtsi:135 */
			zephyr,disabling-power-states = < &state0 &state1 >;                                      /* in zephyr/dts/arm/ti/cc23x0.dtsi:136 */
			status = "okay";                                                                          /* in zephyr/boards/ti/lp_em_cc2340r5/lp_em_cc2340r5.dts:108 */
			pinctrl-0 = < &spi0_sck_default &spi0_mosi_default &spi0_miso_default &spi0_cs_default >; /* in zephyr/boards/ti/lp_em_cc2340r5/lp_em_cc2340r5.dts:109 */
			pinctrl-names = "default";                                                                /* in zephyr/boards/ti/lp_em_cc2340r5/lp_em_cc2340r5.dts:113 */
		};

		/* node '/soc/watchdog@40001000' defined in zephyr/dts/arm/ti/cc23x0.dtsi:140 */
		wdt0: watchdog@40001000 {
			compatible = "ti,cc23x0-wdt"; /* in zephyr/dts/arm/ti/cc23x0.dtsi:141 */
			reg = < 0x40001000 0x310 >;   /* in zephyr/dts/arm/ti/cc23x0.dtsi:142 */
			status = "okay";              /* in zephyr/boards/ti/lp_em_cc2340r5/lp_em_cc2340r5.dts:117 */
		};

		/* node '/soc/rtc@40002000' defined in zephyr/dts/arm/ti/cc23x0.dtsi:146 */
		rtc0: rtc@40002000 {
			compatible = "ti,cc23x0-rtc"; /* in zephyr/dts/arm/ti/cc23x0.dtsi:147 */
			reg = < 0x40002000 0x64 >;    /* in zephyr/dts/arm/ti/cc23x0.dtsi:148 */
			interrupts = < 0x3 0x0 >;     /* in zephyr/dts/arm/ti/cc23x0.dtsi:149 */
			status = "disabled";          /* in zephyr/dts/arm/ti/cc23x0.dtsi:150 */
		};

		/* node '/soc/lgpt@40060000' defined in zephyr/dts/arm/ti/cc23x0.dtsi:153 */
		lgpt0: lgpt@40060000 {
			compatible = "ti,cc23x0-lgpt"; /* in zephyr/dts/arm/ti/cc23x0.dtsi:154 */
			reg = < 0x40060000 0x1d2 >;    /* in zephyr/dts/arm/ti/cc23x0.dtsi:155 */
			max-top-value = < 0xffff >;    /* in zephyr/dts/arm/ti/cc23x0.dtsi:156 */
			interrupts = < 0xd 0x0 >;      /* in zephyr/dts/arm/ti/cc23x0.dtsi:157 */
			clk-prescale = < 0x0 >;        /* in zephyr/dts/arm/ti/cc23x0.dtsi:158 */
			status = "disabled";           /* in zephyr/dts/arm/ti/cc23x0.dtsi:159 */

			/* node '/soc/lgpt@40060000/pwm0' defined in zephyr/dts/arm/ti/cc23x0.dtsi:161 */
			pwm0: pwm0 {
				compatible = "ti,cc23x0-lgpt-pwm"; /* in zephyr/dts/arm/ti/cc23x0.dtsi:162 */
				#pwm-cells = < 0x3 >;              /* in zephyr/dts/arm/ti/cc23x0.dtsi:163 */
				status = "disabled";               /* in zephyr/dts/arm/ti/cc23x0.dtsi:164 */
			};

			/* node '/soc/lgpt@40060000/pwm1' defined in zephyr/dts/arm/ti/cc23x0.dtsi:167 */
			pwm1: pwm1 {
				compatible = "ti,cc23x0-lgpt-pwm"; /* in zephyr/dts/arm/ti/cc23x0.dtsi:168 */
				#pwm-cells = < 0x3 >;              /* in zephyr/dts/arm/ti/cc23x0.dtsi:169 */
				status = "disabled";               /* in zephyr/dts/arm/ti/cc23x0.dtsi:170 */
			};

			/* node '/soc/lgpt@40060000/pwm2' defined in zephyr/dts/arm/ti/cc23x0.dtsi:173 */
			pwm2: pwm2 {
				compatible = "ti,cc23x0-lgpt-pwm"; /* in zephyr/dts/arm/ti/cc23x0.dtsi:174 */
				#pwm-cells = < 0x3 >;              /* in zephyr/dts/arm/ti/cc23x0.dtsi:175 */
				status = "disabled";               /* in zephyr/dts/arm/ti/cc23x0.dtsi:176 */
			};
		};

		/* node '/soc/lgpt@40061000' defined in zephyr/dts/arm/ti/cc23x0.dtsi:180 */
		lgpt1: lgpt@40061000 {
			compatible = "ti,cc23x0-lgpt"; /* in zephyr/dts/arm/ti/cc23x0.dtsi:181 */
			reg = < 0x40061000 0x1d2 >;    /* in zephyr/dts/arm/ti/cc23x0.dtsi:182 */
			max-top-value = < 0xffff >;    /* in zephyr/dts/arm/ti/cc23x0.dtsi:183 */
			interrupts = < 0xe 0x0 >;      /* in zephyr/dts/arm/ti/cc23x0.dtsi:184 */
			clk-prescale = < 0x0 >;        /* in zephyr/boards/ti/lp_em_cc2340r5/lp_em_cc2340r5.dts:132 */
			status = "okay";               /* in zephyr/boards/ti/lp_em_cc2340r5/lp_em_cc2340r5.dts:133 */

			/* node '/soc/lgpt@40061000/pwm0' defined in zephyr/dts/arm/ti/cc23x0.dtsi:188 */
			pwm3: pwm0 {
				compatible = "ti,cc23x0-lgpt-pwm"; /* in zephyr/dts/arm/ti/cc23x0.dtsi:189 */
				#pwm-cells = < 0x3 >;              /* in zephyr/dts/arm/ti/cc23x0.dtsi:190 */
				status = "disabled";               /* in zephyr/dts/arm/ti/cc23x0.dtsi:191 */
			};

			/* node '/soc/lgpt@40061000/pwm1' defined in zephyr/dts/arm/ti/cc23x0.dtsi:194 */
			pwm4: pwm1 {
				compatible = "ti,cc23x0-lgpt-pwm"; /* in zephyr/dts/arm/ti/cc23x0.dtsi:195 */
				#pwm-cells = < 0x3 >;              /* in zephyr/dts/arm/ti/cc23x0.dtsi:196 */
				status = "disabled";               /* in zephyr/dts/arm/ti/cc23x0.dtsi:197 */
			};

			/* node '/soc/lgpt@40061000/pwm2' defined in zephyr/dts/arm/ti/cc23x0.dtsi:200 */
			pwm5: pwm2 {
				compatible = "ti,cc23x0-lgpt-pwm"; /* in zephyr/dts/arm/ti/cc23x0.dtsi:201 */
				#pwm-cells = < 0x3 >;              /* in zephyr/dts/arm/ti/cc23x0.dtsi:202 */
				pinctrl-0 = < &pwm5_default >;     /* in zephyr/boards/ti/lp_em_cc2340r5/lp_em_cc2340r5.dts:142 */
				pinctrl-names = "default";         /* in zephyr/boards/ti/lp_em_cc2340r5/lp_em_cc2340r5.dts:143 */
				status = "okay";                   /* in zephyr/boards/ti/lp_em_cc2340r5/lp_em_cc2340r5.dts:144 */
				phandle = < 0x19 >;                /* in zephyr/boards/ti/lp_em_cc2340r5/lp_em_cc2340r5.dts:62 */
			};
		};

		/* node '/soc/lgpt@40062000' defined in zephyr/dts/arm/ti/cc23x0.dtsi:207 */
		lgpt2: lgpt@40062000 {
			compatible = "ti,cc23x0-lgpt"; /* in zephyr/dts/arm/ti/cc23x0.dtsi:208 */
			reg = < 0x40062000 0x1d2 >;    /* in zephyr/dts/arm/ti/cc23x0.dtsi:209 */
			max-top-value = < 0xffff >;    /* in zephyr/dts/arm/ti/cc23x0.dtsi:210 */
			interrupts = < 0x11 0x0 >;     /* in zephyr/dts/arm/ti/cc23x0.dtsi:211 */
			clk-prescale = < 0x0 >;        /* in zephyr/boards/ti/lp_em_cc2340r5/lp_em_cc2340r5.dts:137 */
			status = "okay";               /* in zephyr/boards/ti/lp_em_cc2340r5/lp_em_cc2340r5.dts:138 */

			/* node '/soc/lgpt@40062000/pwm0' defined in zephyr/dts/arm/ti/cc23x0.dtsi:215 */
			pwm6: pwm0 {
				compatible = "ti,cc23x0-lgpt-pwm"; /* in zephyr/dts/arm/ti/cc23x0.dtsi:216 */
				#pwm-cells = < 0x3 >;              /* in zephyr/dts/arm/ti/cc23x0.dtsi:217 */
				pinctrl-0 = < &pwm6_default >;     /* in zephyr/boards/ti/lp_em_cc2340r5/lp_em_cc2340r5.dts:148 */
				pinctrl-names = "default";         /* in zephyr/boards/ti/lp_em_cc2340r5/lp_em_cc2340r5.dts:149 */
				status = "okay";                   /* in zephyr/boards/ti/lp_em_cc2340r5/lp_em_cc2340r5.dts:150 */
				phandle = < 0x18 >;                /* in zephyr/boards/ti/lp_em_cc2340r5/lp_em_cc2340r5.dts:57 */
			};

			/* node '/soc/lgpt@40062000/pwm1' defined in zephyr/dts/arm/ti/cc23x0.dtsi:221 */
			pwm7: pwm1 {
				compatible = "ti,cc23x0-lgpt-pwm"; /* in zephyr/dts/arm/ti/cc23x0.dtsi:222 */
				#pwm-cells = < 0x3 >;              /* in zephyr/dts/arm/ti/cc23x0.dtsi:223 */
				status = "disabled";               /* in zephyr/dts/arm/ti/cc23x0.dtsi:224 */
			};

			/* node '/soc/lgpt@40062000/pwm2' defined in zephyr/dts/arm/ti/cc23x0.dtsi:227 */
			pwm8: pwm2 {
				compatible = "ti,cc23x0-lgpt-pwm"; /* in zephyr/dts/arm/ti/cc23x0.dtsi:228 */
				#pwm-cells = < 0x3 >;              /* in zephyr/dts/arm/ti/cc23x0.dtsi:229 */
				status = "disabled";               /* in zephyr/dts/arm/ti/cc23x0.dtsi:230 */
			};
		};

		/* node '/soc/lgpt@40063000' defined in zephyr/dts/arm/ti/cc23x0.dtsi:234 */
		lgpt3: lgpt@40063000 {
			compatible = "ti,cc23x0-lgpt"; /* in zephyr/dts/arm/ti/cc23x0.dtsi:235 */
			reg = < 0x40063000 0x1d2 >;    /* in zephyr/dts/arm/ti/cc23x0.dtsi:236 */
			max-top-value = < 0xffffff >;  /* in zephyr/dts/arm/ti/cc23x0.dtsi:237 */
			interrupts = < 0x12 0x0 >;     /* in zephyr/dts/arm/ti/cc23x0.dtsi:238 */
			clk-prescale = < 0x0 >;        /* in zephyr/dts/arm/ti/cc23x0.dtsi:239 */
			status = "disabled";           /* in zephyr/dts/arm/ti/cc23x0.dtsi:240 */

			/* node '/soc/lgpt@40063000/pwm0' defined in zephyr/dts/arm/ti/cc23x0.dtsi:242 */
			pwm9: pwm0 {
				compatible = "ti,cc23x0-lgpt-pwm"; /* in zephyr/dts/arm/ti/cc23x0.dtsi:243 */
				#pwm-cells = < 0x3 >;              /* in zephyr/dts/arm/ti/cc23x0.dtsi:244 */
				status = "disabled";               /* in zephyr/dts/arm/ti/cc23x0.dtsi:245 */
			};

			/* node '/soc/lgpt@40063000/pwm1' defined in zephyr/dts/arm/ti/cc23x0.dtsi:248 */
			pwm10: pwm1 {
				compatible = "ti,cc23x0-lgpt-pwm"; /* in zephyr/dts/arm/ti/cc23x0.dtsi:249 */
				#pwm-cells = < 0x3 >;              /* in zephyr/dts/arm/ti/cc23x0.dtsi:250 */
				status = "disabled";               /* in zephyr/dts/arm/ti/cc23x0.dtsi:251 */
			};

			/* node '/soc/lgpt@40063000/pwm2' defined in zephyr/dts/arm/ti/cc23x0.dtsi:254 */
			pwm11: pwm2 {
				compatible = "ti,cc23x0-lgpt-pwm"; /* in zephyr/dts/arm/ti/cc23x0.dtsi:255 */
				#pwm-cells = < 0x3 >;              /* in zephyr/dts/arm/ti/cc23x0.dtsi:256 */
				status = "disabled";               /* in zephyr/dts/arm/ti/cc23x0.dtsi:257 */
			};
		};

		/* node '/soc/adc@40050000' defined in zephyr/dts/arm/ti/cc23x0.dtsi:261 */
		adc0: adc@40050000 {
			compatible = "ti,cc23x0-adc";                                                /* in zephyr/dts/arm/ti/cc23x0.dtsi:262 */
			reg = < 0x40050000 0xe30 >;                                                  /* in zephyr/dts/arm/ti/cc23x0.dtsi:263 */
			interrupts = < 0xf 0x0 >;                                                    /* in zephyr/dts/arm/ti/cc23x0.dtsi:264 */
			#io-channel-cells = < 0x1 >;                                                 /* in zephyr/dts/arm/ti/cc23x0.dtsi:265 */
			dmas = < &dma 0x3 0x5 >;                                                     /* in zephyr/dts/arm/ti/cc23x0.dtsi:266 */
			dma-names = "dma";                                                           /* in zephyr/dts/arm/ti/cc23x0.dtsi:267 */
			status = "okay";                                                             /* in zephyr/boards/ti/lp_em_cc2340r5/lp_em_cc2340r5.dts:121 */
			pinctrl-0 = < &adc0_ch0 &adc0_ch2 &adc0_ch3 &adc0_ch4 &adc0_ch6 &adc0_ch8 >; /* in zephyr/boards/ti/lp_em_cc2340r5/lp_em_cc2340r5.dts:122 */
			pinctrl-names = "default";                                                   /* in zephyr/boards/ti/lp_em_cc2340r5/lp_em_cc2340r5.dts:128 */
		};

		/* node '/soc/i2c@40038000' defined in zephyr/dts/arm/ti/cc23x0.dtsi:271 */
		i2c0: i2c@40038000 {
			compatible = "ti,cc23x0-i2c";                        /* in zephyr/dts/arm/ti/cc23x0.dtsi:272 */
			#address-cells = < 0x1 >;                            /* in zephyr/dts/arm/ti/cc23x0.dtsi:273 */
			#size-cells = < 0x0 >;                               /* in zephyr/dts/arm/ti/cc23x0.dtsi:274 */
			reg = < 0x40038000 0x820 >;                          /* in zephyr/dts/arm/ti/cc23x0.dtsi:275 */
			interrupts = < 0xc 0x0 >;                            /* in zephyr/dts/arm/ti/cc23x0.dtsi:276 */
			status = "okay";                                     /* in zephyr/boards/ti/lp_em_cc2340r5/lp_em_cc2340r5.dts:154 */
			pinctrl-0 = < &i2c0_scl_default &i2c0_sda_default >; /* in zephyr/boards/ti/lp_em_cc2340r5/lp_em_cc2340r5.dts:155 */
			clock-frequency = < 0x186a0 >;                       /* in zephyr/boards/ti/lp_em_cc2340r5/lp_em_cc2340r5.dts:157 */
			pinctrl-names = "default";                           /* in zephyr/boards/ti/lp_em_cc2340r5/lp_em_cc2340r5.dts:158 */
		};
	};

	/* node '/cpus' defined in zephyr/dts/arm/ti/cc23x0.dtsi:16 */
	cpus {
		#address-cells = < 0x1 >; /* in zephyr/dts/arm/ti/cc23x0.dtsi:17 */
		#size-cells = < 0x0 >;    /* in zephyr/dts/arm/ti/cc23x0.dtsi:18 */

		/* node '/cpus/cpu@0' defined in zephyr/dts/arm/ti/cc23x0.dtsi:20 */
		cpu0: cpu@0 {
			device_type = "cpu";                            /* in zephyr/dts/arm/ti/cc23x0.dtsi:21 */
			compatible = "arm,cortex-m0+";                  /* in zephyr/dts/arm/ti/cc23x0.dtsi:22 */
			clock-frequency = < 0x2dc6c00 >;                /* in zephyr/dts/arm/ti/cc23x0.dtsi:23 */
			reg = < 0x0 >;                                  /* in zephyr/dts/arm/ti/cc23x0.dtsi:24 */
			cpu-power-states = < &state0 &state1 &state2 >; /* in zephyr/dts/arm/ti/cc23x0.dtsi:25 */
		};

		/* node '/cpus/power-states' defined in zephyr/dts/arm/ti/cc23x0.dtsi:28 */
		power-states {

			/* node '/cpus/power-states/state0' defined in zephyr/dts/arm/ti/cc23x0.dtsi:29 */
			state0: state0 {
				compatible = "zephyr,power-state"; /* in zephyr/dts/arm/ti/cc23x0.dtsi:30 */
				power-state-name = "runtime-idle"; /* in zephyr/dts/arm/ti/cc23x0.dtsi:31 */
				min-residency-us = < 0x13b >;      /* in zephyr/dts/arm/ti/cc23x0.dtsi:32 */
				phandle = < 0x6 >;                 /* in zephyr/dts/arm/ti/cc23x0.dtsi:136 */
			};

			/* node '/cpus/power-states/state1' defined in zephyr/dts/arm/ti/cc23x0.dtsi:35 */
			state1: state1 {
				compatible = "zephyr,power-state"; /* in zephyr/dts/arm/ti/cc23x0.dtsi:36 */
				power-state-name = "standby";      /* in zephyr/dts/arm/ti/cc23x0.dtsi:37 */
				min-residency-us = < 0x13b >;      /* in zephyr/dts/arm/ti/cc23x0.dtsi:38 */
				exit-latency-us = < 0xb9 >;        /* in zephyr/dts/arm/ti/cc23x0.dtsi:39 */
				phandle = < 0x7 >;                 /* in zephyr/dts/arm/ti/cc23x0.dtsi:136 */
			};

			/* node '/cpus/power-states/state2' defined in zephyr/dts/arm/ti/cc23x0.dtsi:43 */
			state2: state2 {
				compatible = "zephyr,power-state"; /* in zephyr/dts/arm/ti/cc23x0.dtsi:44 */
				power-state-name = "soft-off";     /* in zephyr/dts/arm/ti/cc23x0.dtsi:45 */
				min-residency-us = < 0x0 >;        /* in zephyr/dts/arm/ti/cc23x0.dtsi:46 */
				exit-latency-us = < 0x0 >;         /* in zephyr/dts/arm/ti/cc23x0.dtsi:47 */
				status = "disabled";               /* in zephyr/dts/arm/ti/cc23x0.dtsi:48 */
				phandle = < 0x16 >;                /* in zephyr/dts/arm/ti/cc23x0.dtsi:25 */
			};
		};
	};

	/* node '/memory@20000000' defined in zephyr/dts/arm/ti/cc23x0.dtsi:53 */
	sram0: memory@20000000 {
		compatible = "mmio-sram";    /* in zephyr/dts/arm/ti/cc23x0.dtsi:54 */
		reg = < 0x20000000 0x9000 >; /* in zephyr/dts/arm/ti/cc2340r5.dtsi:13 */
	};

	/* node '/system-clock' defined in zephyr/dts/arm/ti/cc23x0.dtsi:57 */
	sysclk: system-clock {
		compatible = "fixed-clock";      /* in zephyr/dts/arm/ti/cc23x0.dtsi:58 */
		clock-frequency = < 0x2dc6c00 >; /* in zephyr/dts/arm/ti/cc23x0.dtsi:59 */
		#clock-cells = < 0x0 >;          /* in zephyr/dts/arm/ti/cc23x0.dtsi:60 */
		phandle = < 0x2 >;               /* in zephyr/dts/arm/ti/cc23x0.dtsi:104 */
	};

	/* node '/connector' defined in zephyr/boards/ti/lp_em_cc2340r5/boosterpack_connector.dtsi:9 */
	boosterpack_header: connector {
		compatible = "ti,boosterpack-header";    /* in zephyr/boards/ti/lp_em_cc2340r5/boosterpack_connector.dtsi:10 */
		#gpio-cells = < 0x2 >;                   /* in zephyr/boards/ti/lp_em_cc2340r5/boosterpack_connector.dtsi:11 */
		gpio-map = < 0x3 0x0 &gpio0 0x16 0x0 >,
		           < 0x4 0x0 &gpio0 0x14 0x0 >,
		           < 0x7 0x0 &gpio0 0x12 0x0 >,
		           < 0x8 0x0 &gpio0 0x3 0x0 >,
		           < 0x9 0x0 &gpio0 0x18 0x0 >,
		           < 0xa 0x0 &gpio0 0x0 0x0 >,
		           < 0xc 0x0 &gpio0 0x9 0x0 >,
		           < 0xd 0x0 &gpio0 0xa 0x0 >,
		           < 0xe 0x0 &gpio0 0xc 0x0 >,
		           < 0xf 0x0 &gpio0 0xd 0x0 >,
		           < 0x11 0x0 &gpio0 0x13 0x0 >,
		           < 0x12 0x0 &gpio0 0xb 0x0 >,
		           < 0x17 0x0 &gpio0 0x17 0x0 >,
		           < 0x18 0x0 &gpio0 0x19 0x0 >,
		           < 0x19 0x0 &gpio0 0x1 0x0 >,
		           < 0x1a 0x0 &gpio0 0x2 0x0 >,
		           < 0x1b 0x0 &gpio0 0x5 0x0 >,
		           < 0x1c 0x0 &gpio0 0x7 0x0 >,
		           < 0x24 0x0 &gpio0 0x8 0x0 >,
		           < 0x25 0x0 &gpio0 0x15 0x0 >,
		           < 0x26 0x0 &gpio0 0x6 0x0 >,
		           < 0x27 0x0 &gpio0 0xe 0x0 >,
		           < 0x28 0x0 &gpio0 0xf 0x0 >;  /* in zephyr/boards/ti/lp_em_cc2340r5/boosterpack_connector.dtsi:12 */
	};

	/* node '/leds' defined in zephyr/boards/ti/lp_em_cc2340r5/lp_em_cc2340r5.dts:39 */
	leds {
		compatible = "gpio-leds"; /* in zephyr/boards/ti/lp_em_cc2340r5/lp_em_cc2340r5.dts:40 */

		/* node '/leds/led_0' defined in zephyr/boards/ti/lp_em_cc2340r5/lp_em_cc2340r5.dts:42 */
		led0: led_0 {
			gpios = < &gpio0 0xf 0x0 >; /* in zephyr/boards/ti/lp_em_cc2340r5/lp_em_cc2340r5.dts:43 */
			label = "Green LED";        /* in zephyr/boards/ti/lp_em_cc2340r5/lp_em_cc2340r5.dts:44 */
		};

		/* node '/leds/led_1' defined in zephyr/boards/ti/lp_em_cc2340r5/lp_em_cc2340r5.dts:47 */
		led1: led_1 {
			gpios = < &gpio0 0xe 0x0 >; /* in zephyr/boards/ti/lp_em_cc2340r5/lp_em_cc2340r5.dts:48 */
			label = "Red LED";          /* in zephyr/boards/ti/lp_em_cc2340r5/lp_em_cc2340r5.dts:49 */
		};
	};

	/* node '/pwmleds' defined in zephyr/boards/ti/lp_em_cc2340r5/lp_em_cc2340r5.dts:53 */
	pwmleds {
		compatible = "pwm-leds"; /* in zephyr/boards/ti/lp_em_cc2340r5/lp_em_cc2340r5.dts:54 */

		/* node '/pwmleds/pwm_led_0' defined in zephyr/boards/ti/lp_em_cc2340r5/lp_em_cc2340r5.dts:56 */
		pwm_green: pwm_led_0 {
			pwms = < &pwm6 0x0 0x3e8 0x0 >; /* in zephyr/boards/ti/lp_em_cc2340r5/lp_em_cc2340r5.dts:57 */
			label = "Green PWM LED";        /* in zephyr/boards/ti/lp_em_cc2340r5/lp_em_cc2340r5.dts:58 */
		};

		/* node '/pwmleds/pwm_led_1' defined in zephyr/boards/ti/lp_em_cc2340r5/lp_em_cc2340r5.dts:61 */
		pwm_red: pwm_led_1 {
			pwms = < &pwm5 0x0 0x3e8 0x0 >; /* in zephyr/boards/ti/lp_em_cc2340r5/lp_em_cc2340r5.dts:62 */
			label = "Red PWM LED";          /* in zephyr/boards/ti/lp_em_cc2340r5/lp_em_cc2340r5.dts:63 */
		};
	};

	/* node '/keys' defined in zephyr/boards/ti/lp_em_cc2340r5/lp_em_cc2340r5.dts:67 */
	keys {
		compatible = "gpio-keys"; /* in zephyr/boards/ti/lp_em_cc2340r5/lp_em_cc2340r5.dts:68 */

		/* node '/keys/btn_0' defined in zephyr/boards/ti/lp_em_cc2340r5/lp_em_cc2340r5.dts:70 */
		btn0: btn_0 {
			gpios = < &gpio0 0xa 0x11 >; /* in zephyr/boards/ti/lp_em_cc2340r5/lp_em_cc2340r5.dts:71 */
			label = "Button 1";          /* in zephyr/boards/ti/lp_em_cc2340r5/lp_em_cc2340r5.dts:72 */
			zephyr,code = < 0xb >;       /* in zephyr/boards/ti/lp_em_cc2340r5/lp_em_cc2340r5.dts:73 */
		};

		/* node '/keys/btn_1' defined in zephyr/boards/ti/lp_em_cc2340r5/lp_em_cc2340r5.dts:76 */
		btn1: btn_1 {
			gpios = < &gpio0 0x9 0x11 >; /* in zephyr/boards/ti/lp_em_cc2340r5/lp_em_cc2340r5.dts:77 */
			label = "Button 2";          /* in zephyr/boards/ti/lp_em_cc2340r5/lp_em_cc2340r5.dts:78 */
			zephyr,code = < 0x2 >;       /* in zephyr/boards/ti/lp_em_cc2340r5/lp_em_cc2340r5.dts:79 */
		};
	};

	/* node '/lf_xosc' defined in zephyr/boards/ti/lp_em_cc2340r5/lp_em_cc2340r5.dts:83 */
	lfxosc: lf_xosc {
		compatible = "ti,cc23x0-lf-xosc"; /* in zephyr/boards/ti/lp_em_cc2340r5/lp_em_cc2340r5.dts:84 */
	};
};
